# STM32U595 register map
File version: 1.0
CPU: CM33 r0p1, little endian, MPU, FPU, 4 interrupt priority bits
Registers are 32-bit, read-write, reset 0x0 unless marked. A register's access mark holds for its fields unless they carry their own. Offsets are from the block's base; [hi:lo] are bit positions; {n}, {i} and the like mark numbered series.

## DLYBOS1 — The delay block (DLYB) is used to generate an output clock that is dephased from the input clock
Base 0x420CF000
Same registers: DLYBSD1 0x420C8400, DLYBSD2 0x420C8800, DLYBOS2 0x420CF400, SEC_DLYBSD1 0x520C8400, SEC_DLYBSD2 0x520C8800, SEC_DLYBOS1 0x520CF000, SEC_DLYBOS2 0x520CF400
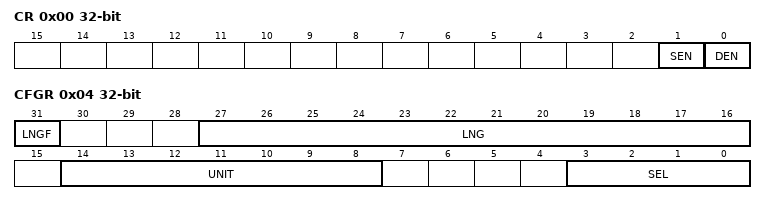
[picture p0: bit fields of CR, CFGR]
0x00 CR — control register
  [1] SEN — OPALPM
  [0] DEN — Operational amplifier Enable
0x04 CFGR access per field — configuration register
  [31] LNGF ro, [27:16] LNG ro, [14:8] UNIT rw, [3:0] SEL rw

## FMAC — Filter Math Accelerator
Base 0x40021400
Same registers: SEC_FMAC 0x50021400
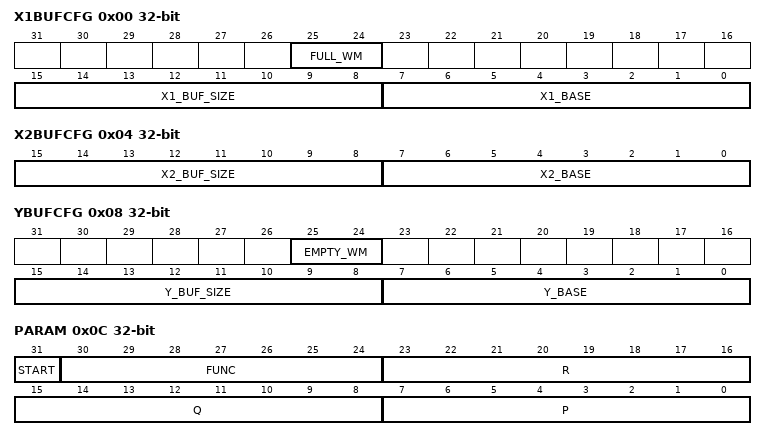
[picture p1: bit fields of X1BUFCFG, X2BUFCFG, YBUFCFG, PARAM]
0x00 X1BUFCFG — FMAC X1 Buffer Configuration register
  [25:24] FULL_WM — Watermark for buffer full flag
  [15:8] X1_BUF_SIZE — Allocated size of X1 buffer in 16-bit words
  [7:0] X1_BASE — Base address of X1 buffer
0x04 X2BUFCFG — FMAC X2 Buffer Configuration register
  [15:8] X2_BUF_SIZE — Size of X2 buffer in 16-bit words
  [7:0] X2_BASE — Base address of X2 buffer
0x08 YBUFCFG — FMAC Y Buffer Configuration register
  [25:24] EMPTY_WM — Watermark for buffer empty flag
  [15:8] Y_BUF_SIZE — Size of Y buffer in 16-bit words
  [7:0] Y_BASE — Base address of Y buffer
0x0C PARAM — FMAC Parameter register
  [31] START — Enable execution
  [30:24] FUNC — Function
  [23:16] R — Input parameter R
  [15:8] Q — Input parameter Q
  [7:0] P — Input parameter P
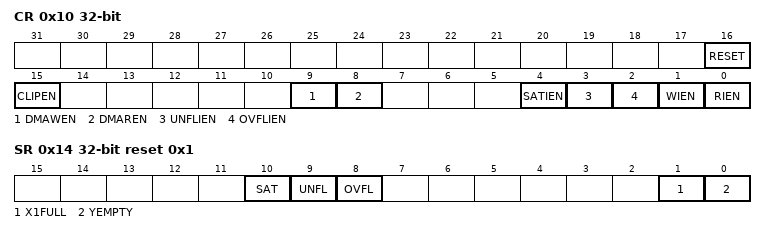
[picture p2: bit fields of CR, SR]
0x10 CR — FMAC Control register
  [16] RESET — Reset FMAC unit
  [15] CLIPEN — Enable clipping
  [9] DMAWEN — Enable DMA write channel requests
  [8] DMAREN — Enable DMA read channel requests
  [4] SATIEN — Enable saturation error interrupts
  [3] UNFLIEN — Enable underflow error interrupts
  [2] OVFLIEN — Enable overflow error interrupts
  [1] WIEN — Enable write interrupt
  [0] RIEN — Enable read interrupt
0x14 SR ro reset 0x1 — FMAC Status register
  [10] SAT — Saturation error flag
  [9] UNFL — Underflow error flag
  [8] OVFL — Overflow error flag
  [1] X1FULL — X1 buffer full flag
  [0] YEMPTY — Y buffer empty flag
0x18 WDATA wo — FMAC Write Data register
  [15:0] WDATA — Write data
0x1C RDATA ro — FMAC Read Data register
  [15:0] RDATA — Read data

## GTZC1_MPCBB1
Base 0x40032C00
Same registers: SEC_GTZC1_MPCBB1 0x50032C00
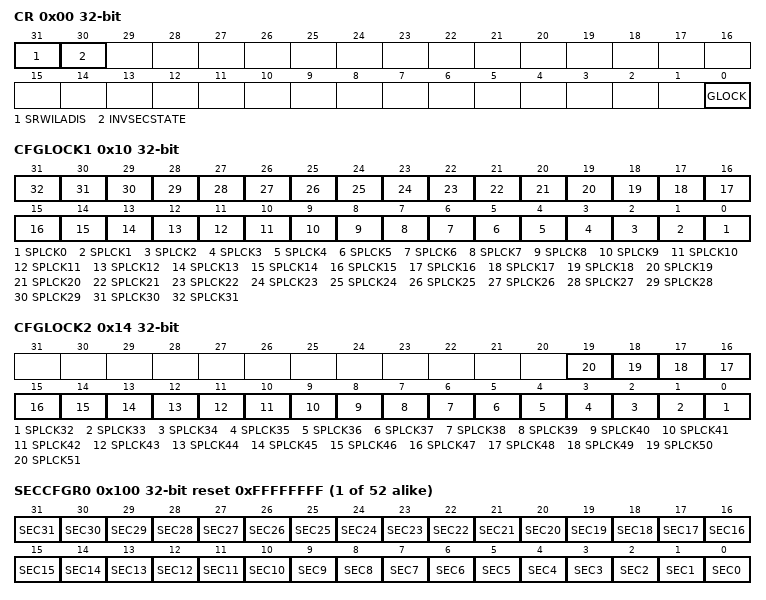
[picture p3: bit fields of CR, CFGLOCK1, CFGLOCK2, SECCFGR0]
0x00 CR — MPCBB control register
  [31] SRWILADIS — secure read/write illegal access disable
  [30] INVSECSTATE — SRAMx clocks security state
  [0] GLOCK — lock the control register of the MPCBB until next reset
0x10 CFGLOCK1 — GTZC1 SRAMz MPCBB configuration lock register 1
  [n] SPLCK{n} (n=0..31) — SPLCK{n}
0x14 CFGLOCK2 — GTZC1 SRAMz MPCBB configuration lock register 2
  [n-32] SPLCK{n} (n=32..51) — SPLCK{n}
{0x100+4i} SECCFGR{i} (i=0..51) reset 0xFFFFFFFF — MPCBBz security configuration for super-block {i} register
  [n] SEC{n} (n=0..31) — SEC{n}
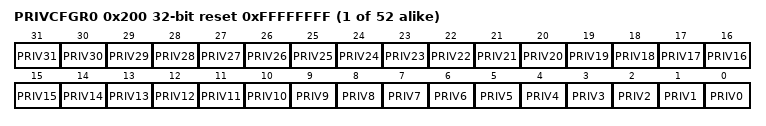
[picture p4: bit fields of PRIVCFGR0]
{0x200+4i} PRIVCFGR{i} (i=0..51) reset 0xFFFFFFFF — MPCBBz privileged configuration for super-block {i} register
  [n] PRIV{n} (n=0..31) — PRIV{n}

## GTZC1_MPCBB2
Base 0x40033000
Same registers: GTZC1_MPCBB3 0x40033400, GTZC1_MPCBB5 0x40033800, SEC_GTZC1_MPCBB2 0x50033000, SEC_GTZC1_MPCBB3 0x50033400, SEC_GTZC1_MPCBB5 0x50033800
Registers as GTZC1_MPCBB1; these are added or differ:
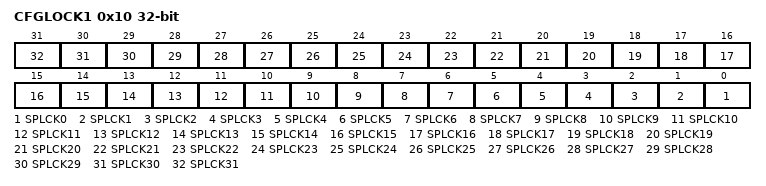
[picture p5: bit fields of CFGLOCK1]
0x10 CFGLOCK1 — GTZC1 SRAMz MPCBB configuration lock register
  [n] SPLCK{n} (n=0..31) — SPLCK{n}

## GTZC2_MPCBB4
Base 0x46023800
Same registers: SEC_GTZC2_MPCBB4 0x56023800
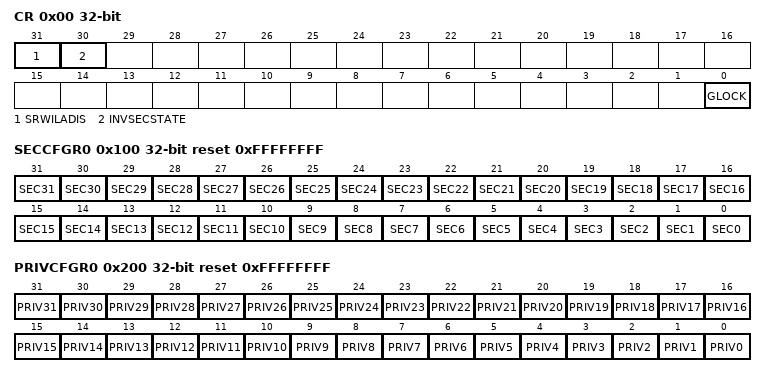
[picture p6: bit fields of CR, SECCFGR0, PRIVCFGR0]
0x00 CR — MPCBB control register
  [31] SRWILADIS — secure read/write illegal access disable
  [30] INVSECSTATE — SRAMx clocks security state
  [0] GLOCK — lock the control register of the MPCBB until next reset
0x10 CFGLOCK — GTZC2 SRAM4 MPCBB configuration lock register
  [n] SPLCK{n} (n=0..0) — Security/privilege configuration lock for super-block {n}
{0x100+4i} SECCFGR{i} (i=0..0) reset 0xFFFFFFFF — MPCBBz security configuration for super-block {i} register
  [n] SEC{n} (n=0..31) — SEC{n}
{0x200+4i} PRIVCFGR{i} (i=0..0) reset 0xFFFFFFFF — MPCBBz privileged configuration for super-block {i} register
  [n] PRIV{n} (n=0..31) — PRIV{n}
